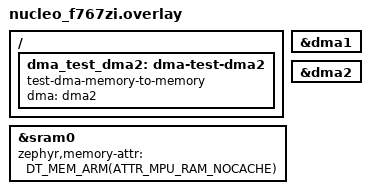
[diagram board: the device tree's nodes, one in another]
/*
 * SPDX-License-Identifier: Apache-2.0
 *
 * Copyright (c) 2023 STMicroelectronics
 */

#include <zephyr/dt-bindings/memory-attr/memory-attr-arm.h>

/ {
	dma_test_dma2: dma-test-dma2 {
		compatible = "test-dma-memory-to-memory";
		dma = <&dma2>;
	};
};

&dma1 {
	status = "okay";
};

&dma2 {
	status = "okay";
};

&sram0 {
	zephyr,memory-attr = <DT_MEM_ARM(ATTR_MPU_RAM_NOCACHE)>;
};
